VERSION ""

NS_ :

BS_:

BU_: Output Logic Input

BO_ 16 output_msg: 8 Output
 SG_ ack_msg : 0|8@1- (1,0) [0|0] "" Vector__XXX

BO_ 9 logic_msg: 8 Logic
 SG_ missile_action_msg : 0|8@1- (1,0) [0|0] "" Vector__XXX

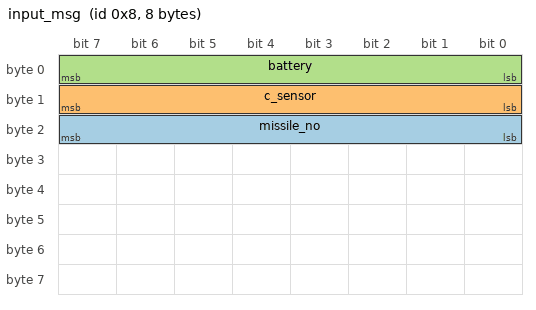
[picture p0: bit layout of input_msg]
BO_ 8 input_msg: 8 Input
 SG_ missile_no : 16|8@1- (1,0) [0|0] "" Vector__XXX
 SG_ c_sensor : 8|8@1- (1,0) [0|0] "" Vector__XXX
 SG_ battery : 0|8@1- (1,0) [0|0] "" Vector__XXX

BO_ 7 Window_Module: 1 Vector__XXX
 SG_ Power_Window : 0|8@1- (1,0) [0|0] "" Vector__XXX

BO_ 3 DoorLockStatus: 1 Logic
 SG_ DoorLock : 0|8@1- (1,0) [0|0] "" Vector__XXX

BO_ 170 ACK: 4 Output

BO_ 2 MirrorFold: 1 Logic
 SG_ MirrorFoldSignal : 0|8@1- (1,0) [0|0] "" Vector__XXX

BO_ 1 CarSpeed: 1 Output
 SG_ Speed : 0|8@1- (1,0) [0|0] "" Vector__XXX

BO_TX_BU_ 1 : Output,Input;

BA_DEF_  "BusType" STRING ;
BA_DEF_DEF_  "BusType" "CAN";
